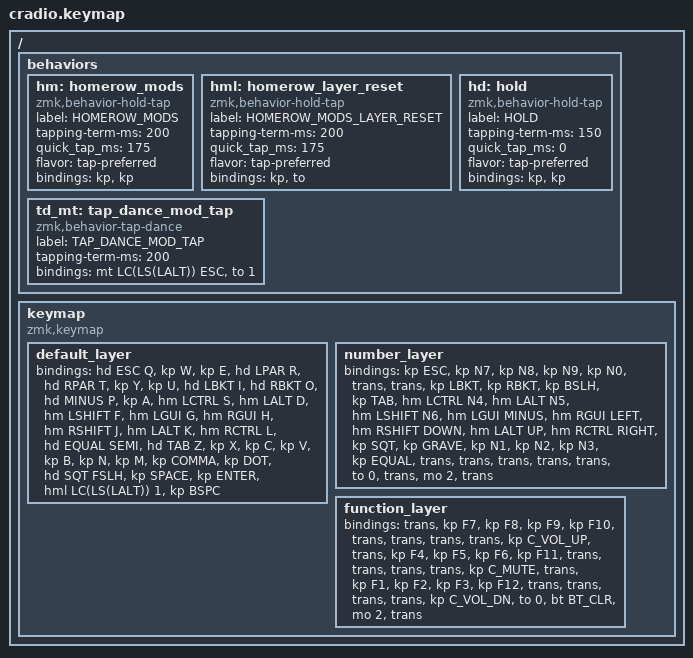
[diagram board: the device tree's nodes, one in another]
/* THIS FILE WAS GENERATED!
 *
 * This file was generated automatically. You may or may not want to
 * edit it directly.https://yasushisakai.com/kinesis_Advantage_360_Pro.html
 */

#include <behaviors.dtsi>
#include <dt-bindings/zmk/keys.h>
#include <dt-bindings/zmk/bt.h>

/ {

  behaviors {
    #include "macros.dtsi"

    hm: homerow_mods {
        compatible = "zmk,behavior-hold-tap";
        label = "HOMEROW_MODS";
        #binding-cells = <2>;
        tapping-term-ms = <200>;
        quick_tap_ms = <175>;
        flavor = "tap-preferred";
        bindings = <&kp>, <&kp>;
    };

    hml: homerow_layer_reset {
        compatible = "zmk,behavior-hold-tap";
        label = "HOMEROW_MODS_LAYER_RESET";
        #binding-cells = <2>;
        tapping-term-ms = <200>;
        quick_tap_ms = <175>;
        flavor = "tap-preferred";
        bindings = <&kp>, <&to>;
    };

    hd: hold {
            compatible = "zmk,behavior-hold-tap";
            label = "HOLD";
            #binding-cells = <2>;
            tapping-term-ms = <150>;
            quick_tap_ms = <0>;
            flavor = "tap-preferred";
            bindings = <&kp>, <&kp>;
    };
    td_mt: tap_dance_mod_tap {
            compatible = "zmk,behavior-tap-dance";
            label = "TAP_DANCE_MOD_TAP";
            #binding-cells = <0>;
            tapping-term-ms = <200>;
            bindings = <&mt LC(LS(LALT)) ESC>, <&to 1>;
    };
  };

keymap {

  compatible = "zmk,keymap";

  default_layer {
    bindings = <
&hd ESC Q  &kp W  &kp E  &hd LPAR R  &hd RPAR T  &kp Y  &kp U  &hd LBKT I  &hd RBKT O  &hd MINUS P  &kp A  &hm LCTRL S  &hm LALT D  &hm LSHIFT F  &hm LGUI G  &hm RGUI H  &hm RSHIFT J  &hm LALT K  &hm RCTRL L  &hd EQUAL SEMI  &hd TAB Z  &kp X  &kp C  &kp V  &kp B  &kp N  &kp M  &kp COMMA  &kp DOT  &hd SQT FSLH  &kp SPACE  &kp ENTER  &hml LC(LS(LALT)) 1  &kp BSPC
    >;
  };

  number_layer {
    bindings = <
&kp ESC  &kp N7  &kp N8  &kp N9  &kp N0  &trans  &trans  &kp LBKT  &kp RBKT  &kp BSLH  &kp TAB  &hm LCTRL N4  &hm LALT N5  &hm LSHIFT N6  &hm LGUI MINUS  &hm RGUI LEFT  &hm RSHIFT DOWN  &hm LALT UP  &hm RCTRL RIGHT  &kp SQT  &kp GRAVE  &kp N1  &kp N2  &kp N3  &kp EQUAL  &trans  &trans  &trans  &trans  &trans  &to 0  &trans  &mo 2  &trans
    >;
  };

  function_layer {
    bindings = <
&trans  &kp F7  &kp F8  &kp F9  &kp F10  &trans  &trans  &trans  &trans  &kp C_VOL_UP  &trans  &kp F4  &kp F5  &kp F6  &kp F11  &trans  &trans  &trans  &trans  &kp C_MUTE  &trans  &kp F1  &kp F2  &kp F3  &kp F12  &trans  &trans  &trans  &trans  &kp C_VOL_DN  &to 0  &bt BT_CLR  &mo 2  &trans
    >;
  };
};};
